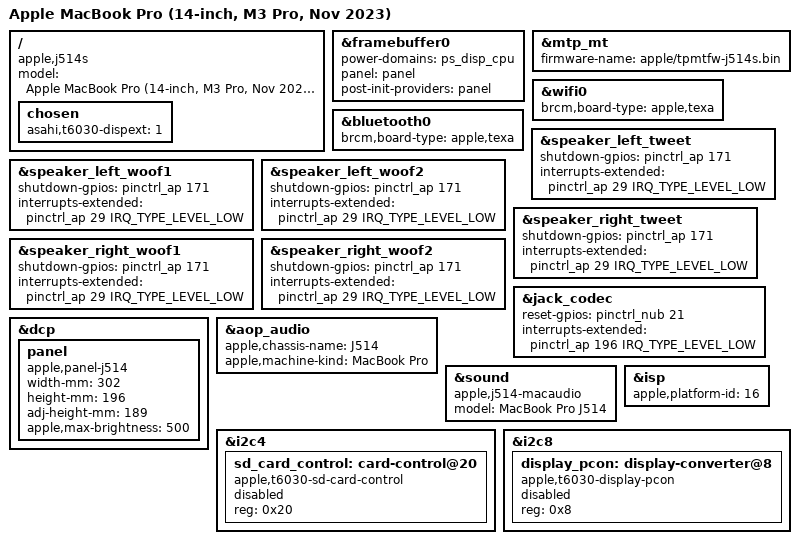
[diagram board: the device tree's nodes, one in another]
// SPDX-License-Identifier: GPL-2.0+ OR MIT
/*
 * MacBook Pro (14-inch, M3 Pro, Nov 2023)
 *
 * target-type: J514s
 *
 * Copyright The Asahi Linux Contributors
 */

/dts-v1/;

#include "t6030.dtsi"
#include "t603x-j514-j516.dtsi"
#include "t603x-j514s-j516s-usb4.dtsi"
#include "t603x-j514s-j516s-hdmi.dtsi"

/ {
	compatible = "apple,j514s", "apple,t6030", "apple,arm-platform";
	model = "Apple MacBook Pro (14-inch, M3 Pro, Nov 2023)";

	chosen {
		asahi,t6030-dispext = "1";
	};
};

&framebuffer0 {
	power-domains = <&ps_disp_cpu>;
	panel = <&panel>;
	post-init-providers = <&panel>;
};

&mtp_mt {
	firmware-name = "apple/tpmtfw-j514s.bin";
};

&wifi0 {
	brcm,board-type = "apple,texa";
};

&bluetooth0 {
	brcm,board-type = "apple,texa";
};

&speaker_left_tweet {
	shutdown-gpios = <&pinctrl_ap 171 GPIO_ACTIVE_HIGH>;
	interrupts-extended = <&pinctrl_ap 29 IRQ_TYPE_LEVEL_LOW>;
};

&speaker_left_woof1 {
	shutdown-gpios = <&pinctrl_ap 171 GPIO_ACTIVE_HIGH>;
	interrupts-extended = <&pinctrl_ap 29 IRQ_TYPE_LEVEL_LOW>;
};

&speaker_left_woof2 {
	shutdown-gpios = <&pinctrl_ap 171 GPIO_ACTIVE_HIGH>;
	interrupts-extended = <&pinctrl_ap 29 IRQ_TYPE_LEVEL_LOW>;
};

&speaker_right_tweet {
	shutdown-gpios = <&pinctrl_ap 171 GPIO_ACTIVE_HIGH>;
	interrupts-extended = <&pinctrl_ap 29 IRQ_TYPE_LEVEL_LOW>;
};

&speaker_right_woof1 {
	shutdown-gpios = <&pinctrl_ap 171 GPIO_ACTIVE_HIGH>;
	interrupts-extended = <&pinctrl_ap 29 IRQ_TYPE_LEVEL_LOW>;
};

&speaker_right_woof2 {
	shutdown-gpios = <&pinctrl_ap 171 GPIO_ACTIVE_HIGH>;
	interrupts-extended = <&pinctrl_ap 29 IRQ_TYPE_LEVEL_LOW>;
};

&jack_codec {
	reset-gpios = <&pinctrl_nub 21 GPIO_ACTIVE_HIGH>;
	interrupts-extended = <&pinctrl_ap 196 IRQ_TYPE_LEVEL_LOW>;
};

&dcp {
	panel: panel {
		compatible = "apple,panel-j514", "apple,panel-mini-led", "apple,panel";
		width-mm = <302>;
		height-mm = <196>;
		adj-height-mm = <189>;
		apple,max-brightness = <500>;
	};
};

&aop_audio {
	apple,chassis-name = "J514";
	apple,machine-kind = "MacBook Pro";
};

&sound {
	compatible = "apple,j514-macaudio", "apple,j314-macaudio", "apple,macaudio";
	model = "MacBook Pro J514";
};

&isp {
	apple,platform-id = <16>;
};

&i2c4 {
	sd_card_control: card-control@20 {
		compatible = "apple,t6030-sd-card-control", "apple,sd-card-control";
		reg = <0x20>;
		status = "disabled";
	};
};

&i2c8 {
	display_pcon: display-converter@8 {
		compatible = "apple,t6030-display-pcon", "apple,display-pcon";
		reg = <0x8>;
		status = "disabled";
	};
};
